# SA3_SS0_SA_UL_0_EIP_76 register map
Vendor: Texas Instruments
Peripheral module from a debugger description file (folder am62P).
Registers are 32-bit, write-only, reset 0x0 unless marked. A register's access mark holds for its fields unless they carry their own. Offsets are as the file gives them; lines under a group give offsets from that group; [hi:lo] are bit positions; {n}, {i} and the like mark numbered series; 'fields as' and 'values as' point back to an identical list; <NAME> marks a mode.

## SA3_SS0_SA_UL_0_EIP_76
{0x0+4i} EIP_76D_8_BCDF_EIP76_REGISTERS_TRNG_INPUT_{i} (i=0..3) — Please refer to eip76d HW Reference Manual for details
  [31:0] TRNG_INPUT_{i}
{0x0+4i} EIP_76D_8_BCDF_EIP76_REGISTERS_TRNG_OUTPUT_{i} ro (i=0..3) — Please refer to eip76d HW Reference Manual for details
  [31:0] TRNG_OUTPUT_{i}
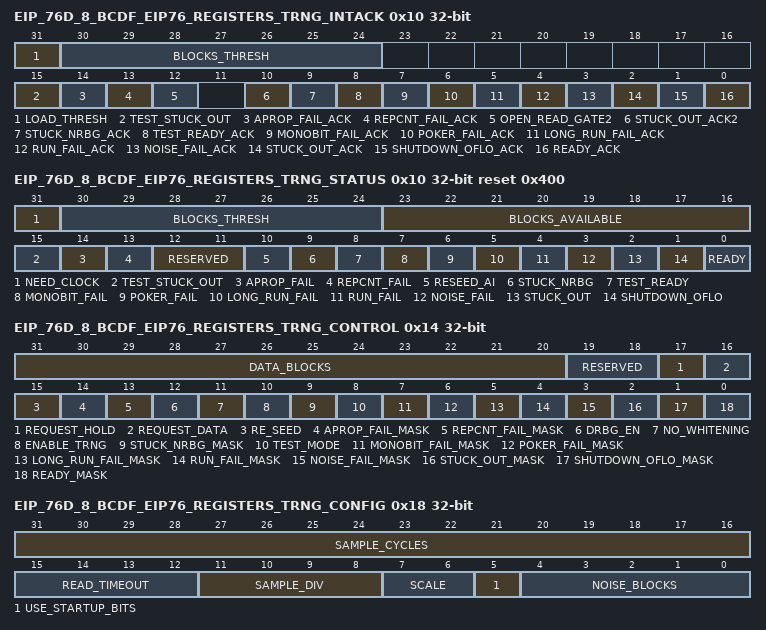
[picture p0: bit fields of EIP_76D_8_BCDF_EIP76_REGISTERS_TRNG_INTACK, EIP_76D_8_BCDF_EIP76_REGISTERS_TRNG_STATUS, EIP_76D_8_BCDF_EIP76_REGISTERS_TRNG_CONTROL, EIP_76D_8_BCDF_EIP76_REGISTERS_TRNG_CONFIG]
0x10 EIP_76D_8_BCDF_EIP76_REGISTERS_TRNG_INTACK — Please refer to eip76d HW Reference Manual for details
  [31] LOAD_THRESH — Please refer to eip76d HW Reference Manual for details
  [30:24] BLOCKS_THRESH — Please refer to eip76d HW Reference Manual for details
  [15] TEST_STUCK_OUT — Please refer to eip76d HW Reference Manual for details
  [14] APROP_FAIL_ACK — Please refer to eip76d HW Reference Manual for details
  [13] REPCNT_FAIL_ACK — Please refer to eip76d HW Reference Manual for details
  [12] OPEN_READ_GATE2 — Please refer to eip76d HW Reference Manual for details
  [10] STUCK_OUT_ACK2 — Please refer to eip76d HW Reference Manual for details
  [9] STUCK_NRBG_ACK — Please refer to eip76d HW Reference Manual for details
  [8] TEST_READY_ACK — Please refer to eip76d HW Reference Manual for details
  [7] MONOBIT_FAIL_ACK — Please refer to eip76d HW Reference Manual for details
  [6] POKER_FAIL_ACK — Please refer to eip76d HW Reference Manual for details
  [5] LONG_RUN_FAIL_ACK — Please refer to eip76d HW Reference Manual for details
  [4] RUN_FAIL_ACK — Please refer to eip76d HW Reference Manual for details
  [3] NOISE_FAIL_ACK — Please refer to eip76d HW Reference Manual for details
  [2] STUCK_OUT_ACK — Please refer to eip76d HW Reference Manual for details
  [1] SHUTDOWN_OFLO_ACK — Please refer to eip76d HW Reference Manual for details
  [0] READY_ACK — Please refer to eip76d HW Reference Manual for details
0x10 EIP_76D_8_BCDF_EIP76_REGISTERS_TRNG_INTACK_secure_mode — Please refer to eip76d HW Reference Manual for details
  [14:0] READY
0x10 EIP_76D_8_BCDF_EIP76_REGISTERS_TRNG_STATUS access not given reset 0x400 — Please refer to eip76d HW Reference Manual for details
  [31] NEED_CLOCK ro — Please refer to eip76d HW Reference Manual for details
  [30:24] BLOCKS_THRESH ro — Please refer to eip76d HW Reference Manual for details
  [23:16] BLOCKS_AVAILABLE ro — Please refer to eip76d HW Reference Manual for details
  [15] TEST_STUCK_OUT ro — Please refer to eip76d HW Reference Manual for details
  [14] APROP_FAIL ro — Please refer to eip76d HW Reference Manual for details
  [13] REPCNT_FAIL ro — Please refer to eip76d HW Reference Manual for details
  [12:11] RESERVED — Please refer to eip76d HW Reference Manual for details (access N/A)
  [10] RESEED_AI ro — Please refer to eip76d HW Reference Manual for details
  [9] STUCK_NRBG ro — Please refer to eip76d HW Reference Manual for details
  [8] TEST_READY ro — Please refer to eip76d HW Reference Manual for details
  [7] MONOBIT_FAIL ro — Please refer to eip76d HW Reference Manual for details
  [6] POKER_FAIL ro — Please refer to eip76d HW Reference Manual for details
  [5] LONG_RUN_FAIL ro — Please refer to eip76d HW Reference Manual for details
  [4] RUN_FAIL ro — Please refer to eip76d HW Reference Manual for details
  [3] NOISE_FAIL ro — Please refer to eip76d HW Reference Manual for details
  [2] STUCK_OUT ro — Please refer to eip76d HW Reference Manual for details
  [1] SHUTDOWN_OFLO ro — Please refer to eip76d HW Reference Manual for details
  [0] READY ro — Please refer to eip76d HW Reference Manual for details
0x14 EIP_76D_8_BCDF_EIP76_REGISTERS_TRNG_CONTROL access not given — Please refer to eip76d HW Reference Manual for details
  [31:20] DATA_BLOCKS rw — Please refer to eip76d HW Reference Manual for details
  [19:18] RESERVED — Please refer to eip76d HW Reference Manual for details (access N/A)
  [17] REQUEST_HOLD rw — Please refer to eip76d HW Reference Manual for details
  [16] REQUEST_DATA wo — Please refer to eip76d HW Reference Manual for details
  [15] RE_SEED rw — Please refer to eip76d HW Reference Manual for details
  [14] APROP_FAIL_MASK rw — Please refer to eip76d HW Reference Manual for details
  [13] REPCNT_FAIL_MASK rw — Please refer to eip76d HW Reference Manual for details
  [12] DRBG_EN rw — Please refer to eip76d HW Reference Manual for details
  [11] NO_WHITENING rw — Please refer to eip76d HW Reference Manual for details
  [10] ENABLE_TRNG rw — Please refer to eip76d HW Reference Manual for details
  [9] STUCK_NRBG_MASK rw — Please refer to eip76d HW Reference Manual for details
  [8] TEST_MODE rw — Please refer to eip76d HW Reference Manual for details
  [7] MONOBIT_FAIL_MASK rw — Please refer to eip76d HW Reference Manual for details
  [6] POKER_FAIL_MASK rw — Please refer to eip76d HW Reference Manual for details
  [5] LONG_RUN_FAIL_MASK rw — Please refer to eip76d HW Reference Manual for details
  [4] RUN_FAIL_MASK rw — Please refer to eip76d HW Reference Manual for details
  [3] NOISE_FAIL_MASK rw — Please refer to eip76d HW Reference Manual for details
  [2] STUCK_OUT_MASK rw — Please refer to eip76d HW Reference Manual for details
  [1] SHUTDOWN_OFLO_MASK rw — Please refer to eip76d HW Reference Manual for details
  [0] READY_MASK rw — Please refer to eip76d HW Reference Manual for details
0x18 EIP_76D_8_BCDF_EIP76_REGISTERS_TRNG_CONFIG rw — Please refer to eip76d HW Reference Manual for details
  [31:16] SAMPLE_CYCLES — Please refer to eip76d HW Reference Manual for details
  [15:12] READ_TIMEOUT — Please refer to eip76d HW Reference Manual for details
  [11:8] SAMPLE_DIV — Please refer to eip76d HW Reference Manual for details
  [7:6] SCALE — Please refer to eip76d HW Reference Manual for details
  [5] USE_STARTUP_BITS — Please refer to eip76d HW Reference Manual for details
  [4:0] NOISE_BLOCKS — Please refer to eip76d HW Reference Manual for details
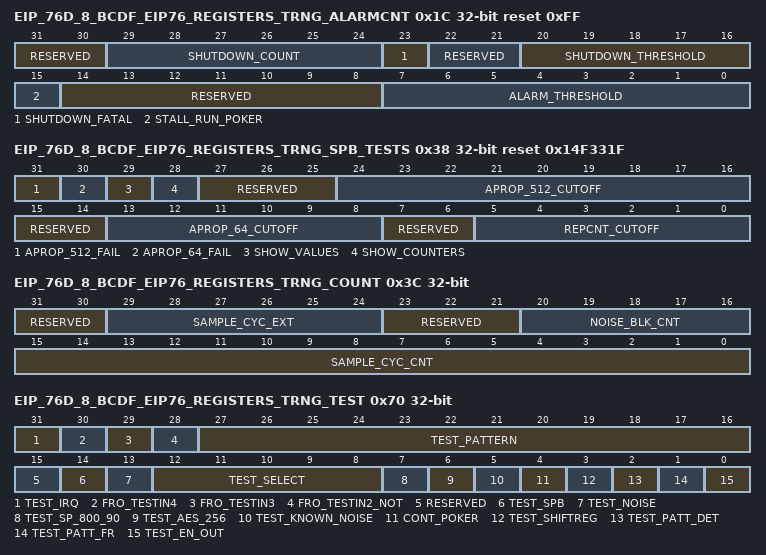
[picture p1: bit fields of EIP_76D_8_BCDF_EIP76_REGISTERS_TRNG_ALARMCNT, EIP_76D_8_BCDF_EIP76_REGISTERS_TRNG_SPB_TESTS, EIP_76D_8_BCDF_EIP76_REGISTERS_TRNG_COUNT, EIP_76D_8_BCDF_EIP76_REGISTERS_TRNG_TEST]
0x1C EIP_76D_8_BCDF_EIP76_REGISTERS_TRNG_ALARMCNT access not given reset 0xFF — Please refer to eip76d HW Reference Manual for details
  [31:30] RESERVED — Please refer to eip76d HW Reference Manual for details (access N/A)
  [29:24] SHUTDOWN_COUNT ro — Please refer to eip76d HW Reference Manual for details
  [23] SHUTDOWN_FATAL rw — Please refer to eip76d HW Reference Manual for details
  [22:21] RESERVED — Please refer to eip76d HW Reference Manual for details (access N/A)
  [20:16] SHUTDOWN_THRESHOLD rw — Please refer to eip76d HW Reference Manual for details
  [15] STALL_RUN_POKER rw — Please refer to eip76d HW Reference Manual for details
  [14:8] RESERVED — Please refer to eip76d HW Reference Manual for details (access N/A)
  [7:0] ALARM_THRESHOLD rw — Please refer to eip76d HW Reference Manual for details
0x20 EIP_76D_8_BCDF_EIP76_REGISTERS_TRNG_FROENABLE rw reset 0xFF — Please refer to eip76d HW Reference Manual for details
  [7:0] TRNG_FROENABLE
0x24 EIP_76D_8_BCDF_EIP76_REGISTERS_TRNG_FRODETUNE rw — Please refer to eip76d HW Reference Manual for details
  [7:0] TRNG_FRODETUNE
0x28 EIP_76D_8_BCDF_EIP76_REGISTERS_TRNG_ALARMMASK rw — Please refer to eip76d HW Reference Manual for details
  [7:0] TRNG_ALARMMASK
0x2C EIP_76D_8_BCDF_EIP76_REGISTERS_TRNG_ALARMSTOP rw — Please refer to eip76d HW Reference Manual for details
  [7:0] TRNG_ALARMSTOP
0x30 EIP_76D_8_BCDF_EIP76_REGISTERS_TRNG_RAW_L rw — Please refer to eip76d HW Reference Manual for details
  [31:0] TRNG_RAW_L
0x34 EIP_76D_8_BCDF_EIP76_REGISTERS_TRNG_RAW_H rw — Please refer to eip76d HW Reference Manual for details
  [31:0] TRNG_RAW_H
0x38 EIP_76D_8_BCDF_EIP76_REGISTERS_TRNG_SPB_TESTS access not given reset 0x14F331F — Please refer to eip76d HW Reference Manual for details
  [31] APROP_512_FAIL rw — Please refer to eip76d HW Reference Manual for details
  [30] APROP_64_FAIL rw — Please refer to eip76d HW Reference Manual for details
  [29] SHOW_VALUES rw — Please refer to eip76d HW Reference Manual for details
  [28] SHOW_COUNTERS rw — Please refer to eip76d HW Reference Manual for details
  [27:25] RESERVED — Please refer to eip76d HW Reference Manual for details (access N/A)
  [24:16] APROP_512_CUTOFF rw — Please refer to eip76d HW Reference Manual for details
  [15:14] RESERVED — Please refer to eip76d HW Reference Manual for details (access N/A)
  [13:8] APROP_64_CUTOFF rw — Please refer to eip76d HW Reference Manual for details
  [7:6] RESERVED — Please refer to eip76d HW Reference Manual for details (access N/A)
  [5:0] REPCNT_CUTOFF rw — Please refer to eip76d HW Reference Manual for details
0x3C EIP_76D_8_BCDF_EIP76_REGISTERS_TRNG_COUNT access not given — Please refer to eip76d HW Reference Manual for details
  [31:30] RESERVED — Please refer to eip76d HW Reference Manual for details (access N/A)
  [29:24] SAMPLE_CYC_EXT ro — Please refer to eip76d HW Reference Manual for details
  [23:21] RESERVED — Please refer to eip76d HW Reference Manual for details (access N/A)
  [20:16] NOISE_BLK_CNT ro — Please refer to eip76d HW Reference Manual for details
  [15:0] SAMPLE_CYC_CNT ro — Please refer to eip76d HW Reference Manual for details
{0x40+4i} EIP_76D_8_BCDF_EIP76_REGISTERS_TRNG_PS_AI_{i} (i=0..11) — Please refer to eip76d HW Reference Manual for details
  [31:0] VECTOR
0x70 EIP_76D_8_BCDF_EIP76_REGISTERS_TRNG_TEST access not given — Please refer to eip76d HW Reference Manual for details
  [31] TEST_IRQ rw — Please refer to eip76d HW Reference Manual for details
  [30] FRO_TESTIN4 rw — Please refer to eip76d HW Reference Manual for details
  [29] FRO_TESTIN3 rw — Please refer to eip76d HW Reference Manual for details
  [28] FRO_TESTIN2_NOT rw — Please refer to eip76d HW Reference Manual for details
  [27:16] TEST_PATTERN rw — Please refer to eip76d HW Reference Manual for details
  [15] RESERVED — Please refer to eip76d HW Reference Manual for details (access N/A)
  [14] TEST_SPB rw — Please refer to eip76d HW Reference Manual for details
  [13] TEST_NOISE rw — Please refer to eip76d HW Reference Manual for details
  [12:8] TEST_SELECT rw — Please refer to eip76d HW Reference Manual for details
  [7] TEST_SP_800_90 rw — Please refer to eip76d HW Reference Manual for details
  [6] TEST_AES_256 rw — Please refer to eip76d HW Reference Manual for details
  [5] TEST_KNOWN_NOISE rw — Please refer to eip76d HW Reference Manual for details
  [4] CONT_POKER rw — Please refer to eip76d HW Reference Manual for details
  [3] TEST_SHIFTREG rw — Please refer to eip76d HW Reference Manual for details
  [2] TEST_PATT_DET rw — Please refer to eip76d HW Reference Manual for details
  [1] TEST_PATT_FR rw — Please refer to eip76d HW Reference Manual for details
  [0] TEST_EN_OUT rw — Please refer to eip76d HW Reference Manual for details
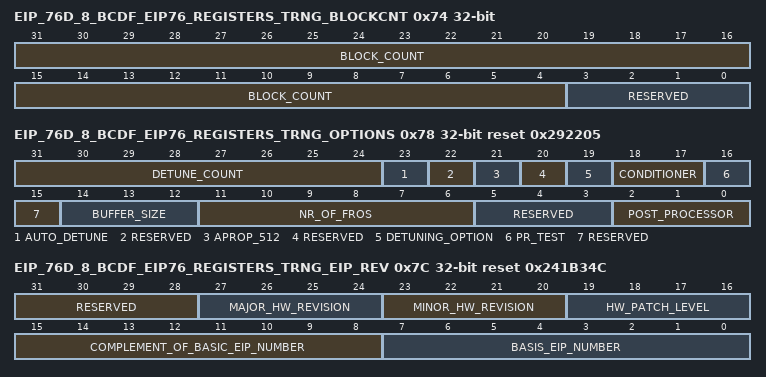
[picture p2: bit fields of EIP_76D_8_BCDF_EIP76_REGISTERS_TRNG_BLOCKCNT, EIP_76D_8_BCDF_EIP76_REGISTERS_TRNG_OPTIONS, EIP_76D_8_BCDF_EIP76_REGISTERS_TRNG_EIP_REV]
0x74 EIP_76D_8_BCDF_EIP76_REGISTERS_TRNG_BLOCKCNT access not given — Please refer to eip76d HW Reference Manual for details
  [31:4] BLOCK_COUNT rw — Please refer to eip76d HW Reference Manual for details
  [3:0] RESERVED — Please refer to eip76d HW Reference Manual for details (access N/A)
0x78 EIP_76D_8_BCDF_EIP76_REGISTERS_TRNG_OPTIONS access not given reset 0x292205 — Please refer to eip76d HW Reference Manual for details
  [31:24] DETUNE_COUNT rw — Please refer to eip76d HW Reference Manual for details
  [23] AUTO_DETUNE rw — Please refer to eip76d HW Reference Manual for details
  [22] RESERVED — Please refer to eip76d HW Reference Manual for details (access N/A)
  [21] APROP_512 ro — Please refer to eip76d HW Reference Manual for details
  [20] RESERVED — Please refer to eip76d HW Reference Manual for details (access N/A)
  [19] DETUNING_OPTION ro — Please refer to eip76d HW Reference Manual for details
  [18:17] CONDITIONER ro — Please refer to eip76d HW Reference Manual for details
  [16] PR_TEST ro — Please refer to eip76d HW Reference Manual for details
  [15] RESERVED — Please refer to eip76d HW Reference Manual for details (access N/A)
  [14:12] BUFFER_SIZE ro — Please refer to eip76d HW Reference Manual for details
  [11:6] NR_OF_FROS ro — Please refer to eip76d HW Reference Manual for details
  [5:3] RESERVED — Please refer to eip76d HW Reference Manual for details (access N/A)
  [2:0] POST_PROCESSOR ro — Please refer to eip76d HW Reference Manual for details
0x7C EIP_76D_8_BCDF_EIP76_REGISTERS_TRNG_EIP_REV access not given reset 0x241B34C — Please refer to eip76d HW Reference Manual for details
  [31:28] RESERVED — Please refer to eip76d HW Reference Manual for details (access N/A)
  [27:24] MAJOR_HW_REVISION ro — Please refer to eip76d HW Reference Manual for details
  [23:20] MINOR_HW_REVISION ro — Please refer to eip76d HW Reference Manual for details
  [19:16] HW_PATCH_LEVEL ro — Please refer to eip76d HW Reference Manual for details
  [15:8] COMPLEMENT_OF_BASIC_EIP_NUMBER ro — Please refer to eip76d HW Reference Manual for details
  [7:0] BASIS_EIP_NUMBER ro — Please refer to eip76d HW Reference Manual for details
